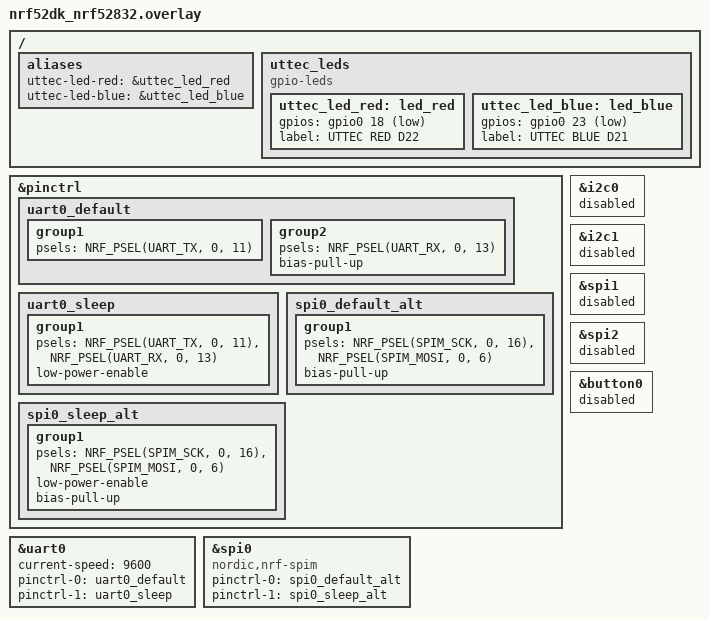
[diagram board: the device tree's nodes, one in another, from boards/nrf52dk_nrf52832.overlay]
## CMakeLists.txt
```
cmake_minimum_required(VERSION 3.20.0)
find_package(Zephyr REQUIRED HINTS $ENV{ZEPHYR_BASE})
project(lora_rx_display)

target_sources(app PRIVATE
	src/main.c
	src/sw_uart.c
)
```

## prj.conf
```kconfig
# UART0 (HW) for LoRa RX — interrupt driven
CONFIG_SERIAL=y
CONFIG_UART_INTERRUPT_DRIVEN=y
CONFIG_UART_USE_RUNTIME_CONFIGURE=y

# SPI0 for SW-UART TX4 (USB-VCOM display)
CONFIG_SPI=y
CONFIG_SOC_NRF52832_ALLOW_SPIM_DESPITE_PAN_58=y

# GPIO
CONFIG_GPIO=y

# RTT console for build-time debug
CONFIG_USE_SEGGER_RTT=y
CONFIG_RTT_CONSOLE=y
CONFIG_UART_CONSOLE=n
CONFIG_CONSOLE=y
CONFIG_PRINTK=y

# Ring buffer for RX byte queuing
CONFIG_RING_BUFFER=y

# Reduce code size
CONFIG_BOOT_BANNER=n
```

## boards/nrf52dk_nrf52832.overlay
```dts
/*
 * UTTEC BLE Module — LoRa RX display (PCA10100 측, 2026-06-07)
 *
 *   HW UART0 (P0.11 TX / P0.13 RX, 9600 8N1) → LoRa E22 RXD/TXD  ★ LoRa RX
 *   SPI0 MOSI (P0.06) → SW-UART TX4 (9600) → PCA10100 USB-VCOM display
 *
 *   LoRa Normal transparent mode (M0=0, M1=0):
 *     M0  = P0.17 (J28 Pin 6)
 *     M1  = P0.19 (J28 Pin 8)
 *     AUX = P0.20 (J28 Pin 10, input, unused)
 *
 *   LED: BLUE P0.23 / RED P0.18 — RX byte 수신 시 RED 토글, line 완료 시 BLUE 토글
 *
 *   J28 14pin 핀맵 (사용자 박제 2026-06-09):
 *     Pin 1  P0.11  LoRa E22 RXD ← UART0 TX (auto setup)
 *     Pin 3  P0.13  LoRa E22 TXD → UART0 RX
 *     Pin 5  (미확정)
 *     Pin 6  P0.17  LoRa M0 (Normal = LOW)
 *     Pin 8  P0.19  LoRa M1 (Normal = LOW)
 *     Pin 10 P0.20  LoRa AUX (input, unused)
 *     Pin 11 3.3V   전원 ⭐
 *     Pin 12 P0.04  Relay (active low buzzer, level<400 → ON) ⭐ 신규
 *     Pin 13 GND    접지 ⭐
 *     Pin 14 (미확정)
 */

&pinctrl {
	/* UART0 = LoRa (TX=P0.11, RX=P0.13, 9600 8N1) */
	uart0_default: uart0_default {
		group1 {
			psels = <NRF_PSEL(UART_TX, 0, 11)>;
		};
		group2 {
			psels = <NRF_PSEL(UART_RX, 0, 13)>;
			bias-pull-up;
		};
	};

	uart0_sleep: uart0_sleep {
		group1 {
			psels = <NRF_PSEL(UART_TX, 0, 11)>,
				<NRF_PSEL(UART_RX, 0, 13)>;
			low-power-enable;
		};
	};

	/* SPI0 MOSI = SW-UART TX4 (USB-VCOM, P0.06, 1 MHz SPI for 9600 baud).
	 * dummy SCK = P0.16 (J28 미노출, free). */
	spi0_default_alt: spi0_default_alt {
		group1 {
			psels = <NRF_PSEL(SPIM_SCK, 0, 16)>,
				<NRF_PSEL(SPIM_MOSI, 0, 6)>;
			bias-pull-up;
		};
	};

	spi0_sleep_alt: spi0_sleep_alt {
		group1 {
			psels = <NRF_PSEL(SPIM_SCK, 0, 16)>,
				<NRF_PSEL(SPIM_MOSI, 0, 6)>;
			low-power-enable;
			bias-pull-up;
		};
	};
};

&uart0 {
	status = "okay";
	current-speed = <9600>;   /* target REG0=0x60: 9600 baud + 0.3k air (max range, max TX power) */
	pinctrl-0 = <&uart0_default>;
	pinctrl-1 = <&uart0_sleep>;
	pinctrl-names = "default", "sleep";
};

&i2c0 { status = "disabled"; };
&i2c1 { status = "disabled"; };

&spi0 {
	status = "okay";
	compatible = "nordic,nrf-spim";
	pinctrl-0 = <&spi0_default_alt>;
	pinctrl-1 = <&spi0_sleep_alt>;
	pinctrl-names = "default", "sleep";
};

&spi1 { status = "disabled"; };
&spi2 { status = "disabled"; };

/* PCA10040 board DT가 P0.13을 sw0 (button0)으로 reserve.
 * UART0 RX와 충돌 막기 위해 button0 비활성. */
&button0 { status = "disabled"; };

/ {
	aliases {
		uttec-led-red = &uttec_led_red;
		uttec-led-blue = &uttec_led_blue;
	};

	uttec_leds {
		compatible = "gpio-leds";
		uttec_led_red: led_red {
			gpios = <&gpio0 18 GPIO_ACTIVE_LOW>;
			label = "UTTEC RED D22";
		};
		uttec_led_blue: led_blue {
			gpios = <&gpio0 23 GPIO_ACTIVE_LOW>;
			label = "UTTEC BLUE D21";
		};
	};
};
```

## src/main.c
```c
/*
 * UTTEC BLE Module — LoRa RX echo (받은 그대로 USB-VCOM display, 2026-06-07)
 *
 *   HW UART0 (P0.11 TX / P0.13 RX, 9600 8N1) ← LoRa E22 (REG0=0x60)
 *   SPI0 MOSI (P0.06, SW-UART 9600) → USB-VCOM display
 *
 *   동작:
 *     1) 부팅 시 E22 setup (target REG0=0x60 자동 확인·write)
 *     2) UART0 ISR로 LoRa byte 수신 → ring buffer
 *     3) '\n' (0x0A) 만나면 line 종료 → USB-VCOM에 그대로 echo
 *     4) byte 수신 시 RED LED toggle / line 완성 시 BLUE LED toggle
 *
 *   메시지 포맷 (TX 측 결정): "tx<N>:<센서값>\r\n"
 *     예: "tx1:377\r\n"
 *   RX는 prefix 안 붙이고 받은 그대로 display.
 */

#include <zephyr/kernel.h>
#include <zephyr/sys/printk.h>
#include <zephyr/device.h>
#include <zephyr/drivers/gpio.h>
#include <zephyr/drivers/uart.h>
#include <zephyr/sys/ring_buffer.h>
#include <stdio.h>
#include <stdlib.h>
#include <string.h>

#include "sw_uart.h"

#define E22_M0_PIN   17
#define E22_M1_PIN   19
#define E22_AUX_PIN  20

/* Buzzer/relay alarm — J28 Pin 12 (P0.04, active low).
 * Line buffer 완성 시 "tx<N>:<level>\r\n" 파싱 → level 비교.
 *   level <  ALARM_THRESHOLD → LOW (ON, beep)
 *   level >= ALARM_THRESHOLD → HIGH (OFF)
 * 파싱 실패 (prefix 불일치 등) 시 직전 상태 유지. */
#define RELAY_PIN          4
#define ALARM_THRESHOLD    400
#define RELAY_ON_LEVEL     0
#define RELAY_OFF_LEVEL    1

#define LINE_BUF_SIZE   64

static const struct gpio_dt_spec led_red =
	GPIO_DT_SPEC_GET(DT_ALIAS(uttec_led_red), gpios);
static const struct gpio_dt_spec led_blue =
	GPIO_DT_SPEC_GET(DT_ALIAS(uttec_led_blue), gpios);
static const struct device *gpio0 = DEVICE_DT_GET(DT_NODELABEL(gpio0));
static const struct device *uart_e22 = DEVICE_DT_GET(DT_NODELABEL(uart0));

static struct sw_uart tx4;

RING_BUF_DECLARE(rx_rb, 512);

static void uart_isr(const struct device *dev, void *user_data)
{
	ARG_UNUSED(user_data);
	while (uart_irq_update(dev) && uart_irq_is_pending(dev)) {
		if (uart_irq_rx_ready(dev)) {
			uint8_t buf[32];
			int n = uart_fifo_read(dev, buf, sizeof(buf));
			if (n > 0) ring_buf_put(&rx_rb, buf, n);
		}
	}
}

static const uint8_t target_cfg[9] = {
	0x00, 0x00, 0x00, 0x60, 0x00, 0x48, 0x80, 0x00, 0x00
};

static void set_mode(int m0, int m1, int settle_ms)
{
	gpio_pin_set(gpio0, E22_M0_PIN, m0);
	gpio_pin_set(gpio0, E22_M1_PIN, m1);
	k_msleep(settle_ms);
}

static int wait_aux_high(int timeout_ms)
{
	int64_t t0 = k_uptime_get();
	while (k_uptime_get() - t0 < timeout_ms) {
		if (gpio_pin_get(gpio0, E22_AUX_PIN) == 1) return (int)(k_uptime_get() - t0);
		k_msleep(1);
	}
	return -1;
}

static void rx_drain(void)
{
	uint8_t b;
	while (ring_buf_get(&rx_rb, &b, 1) == 1) { }
}

static int recv_bytes(uint8_t *out, size_t want, int timeout_ms)
{
	int64_t t0 = k_uptime_get();
	size_t got = 0;
	while (k_uptime_get() - t0 < timeout_ms && got < want) {
		uint8_t b;
		if (ring_buf_get(&rx_rb, &b, 1) == 1) out[got++] = b;
		else k_msleep(1);
	}
	return (int)got;
}

static int uart_set_baud(uint32_t baud)
{
	struct uart_config cfg = {
		.baudrate = baud, .parity = UART_CFG_PARITY_NONE,
		.stop_bits = UART_CFG_STOP_BITS_1, .data_bits = UART_CFG_DATA_BITS_8,
		.flow_ctrl = UART_CFG_FLOW_CTRL_NONE,
	};
	return uart_configure(uart_e22, &cfg);
}

static int read_all_reg(uint8_t *cfg9)
{
	rx_drain();
	uint8_t cmd[3] = { 0xC1, 0x00, 0x09 };
	for (size_t i = 0; i < sizeof(cmd); i++) uart_poll_out(uart_e22, cmd[i]);
	uint8_t resp[16];
	int n = recv_bytes(resp, 12, 500);
	if (n >= 12 && resp[0] == 0xC1 && resp[1] == 0x00 && resp[2] == 0x09) {
		memcpy(cfg9, &resp[3], 9);
		return 1;
	}
	return 0;
}

static int write_all_reg(const uint8_t *cfg9)
{
	rx_drain();
	uint8_t cmd[12] = { 0xC0, 0x00, 0x09 };
	memcpy(&cmd[3], cfg9, 9);
	for (size_t i = 0; i < sizeof(cmd); i++) uart_poll_out(uart_e22, cmd[i]);
	uint8_t resp[16];
	int n = recv_bytes(resp, 12, 1000);
	return (n >= 12 && (resp[0] == 0xC1 || resp[0] == 0xC0));
}

static void emit(const char *fmt, ...)
{
	char buf[96];
	va_list ap;
	va_start(ap, fmt);
	int n = vsnprintf(buf, sizeof(buf), fmt, ap);
	va_end(ap);
	if (n > 0) sw_uart_write(&tx4, (const uint8_t *)buf, (size_t)n);
}

static void e22_config(void)
{
	emit("\r\n[Cfg] E22 setup\r\n");
	set_mode(0, 0, 100); wait_aux_high(500);
	set_mode(0, 1, 50); wait_aux_high(500);
	uart_set_baud(9600); k_msleep(50); rx_drain();

	uint8_t before[9];
	if (!read_all_reg(before)) { emit("  read fail\r\n"); goto restore; }
	if (memcmp(before, target_cfg, 9) == 0) { emit("  already OK\r\n"); goto restore; }

	emit("  REG0=%02X -> write 0x60\r\n", before[3]);
	if (write_all_reg(target_cfg)) {
		wait_aux_high(800); k_msleep(100);
		uint8_t after[9];
		if (read_all_reg(after) && memcmp(after, target_cfg, 9) == 0) {
			emit("  write OK\r\n");
		} else emit("  verify fail\r\n");
	} else emit("  write fail\r\n");

restore:
	uart_set_baud(9600); k_msleep(50);
	set_mode(0, 0, 100); wait_aux_high(500); rx_drain();
}

int main(void)
{
	gpio_pin_configure(gpio0, E22_M0_PIN, GPIO_OUTPUT_LOW);
	gpio_pin_configure(gpio0, E22_M1_PIN, GPIO_OUTPUT_LOW);
	gpio_pin_configure(gpio0, E22_AUX_PIN, GPIO_INPUT | GPIO_PULL_UP);
	gpio_pin_configure_dt(&led_red, GPIO_OUTPUT_INACTIVE);
	gpio_pin_configure_dt(&led_blue, GPIO_OUTPUT_INACTIVE);

	/* Buzzer/relay P0.04 active low — 부팅 시 HIGH (OFF) */
	gpio_pin_configure(gpio0, RELAY_PIN, GPIO_OUTPUT_HIGH);

	sw_uart_init(&tx4, DEVICE_DT_GET(DT_NODELABEL(spi0)), SW_UART_BAUD_9600);
	k_msleep(300);
	emit("\r\nUTTEC RX: LoRa HW UART0 echo (line by \\n)\r\n");

	uart_irq_callback_set(uart_e22, uart_isr);
	uart_irq_rx_enable(uart_e22);
	k_msleep(50);

	e22_config();
	emit("[Loop] listening...\r\n");

	uint8_t line_buf[LINE_BUF_SIZE];
	size_t line_len = 0;

	while (1) {
		uint8_t b;
		if (ring_buf_get(&rx_rb, &b, 1) == 1) {
			gpio_pin_toggle_dt(&led_red);

			if (line_len < LINE_BUF_SIZE) {
				line_buf[line_len++] = b;
			}

			if (b == '\n' || line_len >= LINE_BUF_SIZE) {
				/* line emit — 받은 그대로 (TX 메시지에 \r\n 포함되어 있음) */
				sw_uart_write(&tx4, line_buf, line_len);
				gpio_pin_toggle_dt(&led_blue);

				/* Parse: ':' 위치만 찾고 그 뒤 숫자 → level.
				 * Prefix tolerance — TX PSEL switch 후 첫 byte 't' 손실 함정 회피.
				 * line_buf는 NUL 미종료라 tmp로 복사 후 strtol. */
				char tmp[LINE_BUF_SIZE + 1];
				size_t cp = line_len < LINE_BUF_SIZE ? line_len : LINE_BUF_SIZE;
				memcpy(tmp, line_buf, cp);
				tmp[cp] = '\0';
				char *colon = strchr(tmp, ':');
				if (colon) {
					char *endp = NULL;
					long level = strtol(colon + 1, &endp, 10);
					if (endp != colon + 1) {
						int alarm_now = (level < ALARM_THRESHOLD);
						gpio_pin_set(gpio0, RELAY_PIN,
							alarm_now ? RELAY_ON_LEVEL : RELAY_OFF_LEVEL);

						char alm[48];
						int an = snprintf(alm, sizeof(alm),
							alarm_now ?
							"*** ALARM level=%ld (<%d)\r\n" :
							"--- ok    level=%ld (>=%d)\r\n",
							level, ALARM_THRESHOLD);
						if (an > 0) sw_uart_write(&tx4,
							(const uint8_t *)alm, an);
					}
				}

				line_len = 0;
			}
		} else {
			k_msleep(2);
		}
	}
	return 0;
}
```
